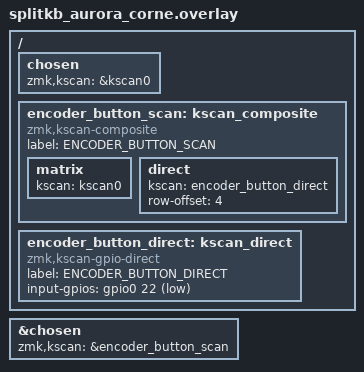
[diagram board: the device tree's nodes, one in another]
/ {
    chosen {
        zmk,kscan = &kscan0;
    };

    // Wir definieren einen zusätzlichen Key-Scanner für den Direkt-Pin
    encoder_button_scan: kscan_composite {
        compatible = "zmk,kscan-composite";
        label = "ENCODER_BUTTON_SCAN";
        #binding-cells = <0>;

        // Bindet die normale Matrix ein
        matrix {
            kscan = <&kscan0>;
        };

        // Bindet den einzelnen Pin P0.22 ein
        direct {
            kscan = <&encoder_button_direct>;
            row-offset = <4>; // Wir schieben den Button in eine "virtuelle" 5. Reihe
        };
    };

    encoder_button_direct: kscan_direct {
        compatible = "zmk,kscan-gpio-direct";
        label = "ENCODER_BUTTON_DIRECT";
        input-gpios = <&gpio0 22 (GPIO_ACTIVE_LOW | GPIO_PULL_UP)>;
    };
};

// ZMK sagen, dass es den kombinierten Scanner nutzen soll
&chosen {
    zmk,kscan = &encoder_button_scan;
};
